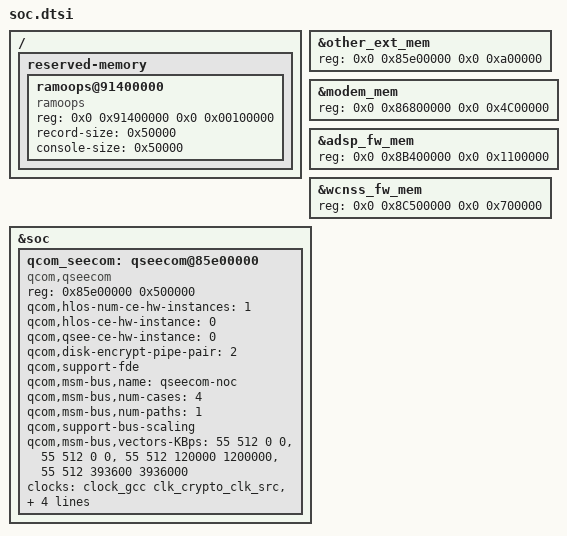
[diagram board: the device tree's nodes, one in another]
&other_ext_mem {
	reg = <0x0 0x85e00000 0x0 0xa00000>;
};

&modem_mem {
	reg = <0x0 0x86800000 0x0 0x4C00000>;
};

&adsp_fw_mem {
	reg = <0x0 0x8B400000 0x0 0x1100000>;
};

&wcnss_fw_mem {
	reg = <0x0 0x8C500000 0x0 0x700000>;
};

/ {
	reserved-memory {
		ramoops@91400000 {
			compatible = "ramoops";
			reg = <0x0 0x91400000 0x0 0x00100000>;
			record-size = <0x50000>;
			console-size = <0x50000>;
		};
	};
};

&soc {
	/delete-node/ qseecom@84a00000;
	qcom_seecom: qseecom@85e00000 {
		compatible = "qcom,qseecom";
		reg = <0x85e00000 0x500000>;
		reg-names = "secapp-region";
		qcom,hlos-num-ce-hw-instances = <1>;
		qcom,hlos-ce-hw-instance = <0>;
		qcom,qsee-ce-hw-instance = <0>;
		qcom,disk-encrypt-pipe-pair = <2>;
		qcom,support-fde;
		qcom,msm-bus,name = "qseecom-noc";
		qcom,msm-bus,num-cases = <4>;
		qcom,msm-bus,num-paths = <1>;
		qcom,support-bus-scaling;
		qcom,msm-bus,vectors-KBps =
			<55 512 0 0>,
			<55 512 0 0>,
			<55 512 120000 1200000>,
			<55 512 393600 3936000>;
		clocks = <&clock_gcc clk_crypto_clk_src>,
			<&clock_gcc clk_gcc_crypto_clk>,
			<&clock_gcc clk_gcc_crypto_ahb_clk>,
			<&clock_gcc clk_gcc_crypto_axi_clk>;
		clock-names = "core_clk_src", "core_clk",
			"iface_clk", "bus_clk";
		qcom,ce-opp-freq = <100000000>;
	};
};
